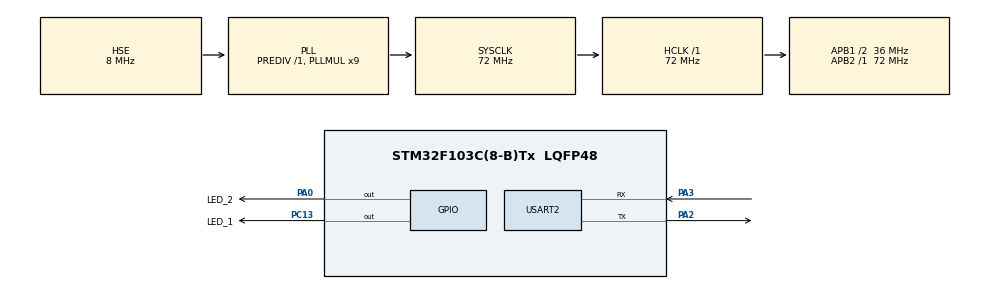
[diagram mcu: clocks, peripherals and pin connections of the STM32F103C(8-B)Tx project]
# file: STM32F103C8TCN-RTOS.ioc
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FREERTOS.Tasks01=defaultTask,0,128,StartDefaultTask,Default,NULL,Dynamic,NULL,NULL;myTask02,-3,128,StartTask02,Default,NULL,Dynamic,NULL,NULL
FREERTOS.configUSE_NEWLIB_REENTRANT=1
Mcu.Family=STM32F1
Mcu.Name=STM32F103C(8-B)Tx
Mcu.Package=LQFP48
NVIC.PriorityGroup=NVIC_PRIORITYGROUP_4
NVIC.TIM1_UP_IRQn=true\:15\:0\:false\:false\:true\:false\:false\:true\:true
NVIC.TimeBase=TIM1_UP_IRQn
NVIC.TimeBaseIP=TIM1
PA0-WKUP.GPIO_Label=LED_2
PA0-WKUP.Signal=GPIO_Output
PA2.Mode=Asynchronous
PA2.Signal=USART2_TX
PA3.Mode=Asynchronous
PA3.Signal=USART2_RX
PC13-TAMPER-RTC.GPIO_Label=LED_1
PC13-TAMPER-RTC.Signal=GPIO_Output
PD0-OSC_IN.Mode=HSE-External-Oscillator
PD0-OSC_IN.Signal=RCC_OSC_IN
PD1-OSC_OUT.Mode=HSE-External-Oscillator
PD1-OSC_OUT.Signal=RCC_OSC_OUT
ProjectManager.HeapSize=0x200
ProjectManager.StackSize=0x400
ProjectManager.TargetToolchain=STM32CubeIDE
RCC.AHBFreq_Value=72000000
RCC.APB1CLKDivider=RCC_HCLK_DIV2
RCC.APB1Freq_Value=36000000
RCC.APB1TimFreq_Value=72000000
RCC.APB2Freq_Value=72000000
RCC.APB2TimFreq_Value=72000000
RCC.HCLKFreq_Value=72000000
RCC.PLLMUL=RCC_PLL_MUL9
RCC.PLLSourceVirtual=RCC_PLLSOURCE_HSE
RCC.SYSCLKFreq_VALUE=72000000
RCC.SYSCLKSource=RCC_SYSCLKSOURCE_PLLCLK
RCC.USBFreq_Value=72000000
USART2.VirtualMode=VM_ASYNC
VP_FREERTOS_VS_CMSIS_V1.Mode=CMSIS_V1
VP_SYS_VS_tim1.Mode=TIM1
board=custom

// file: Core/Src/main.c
/* USER CODE BEGIN Header */
/**
  ******************************************************************************
  * @file           : main.c
  * @brief          : Main program body
  ******************************************************************************
  * @attention
  *
  * Copyright (c) 2023 STMicroelectronics.
  * All rights reserved.
  *
  * This software is licensed under terms that can be found in the LICENSE file
  * in the root directory of this software component.
  * If no LICENSE file comes with this software, it is provided AS-IS.
  *
  ******************************************************************************
  */
/* USER CODE END Header */
#include "main.h"
#include "cmsis_os.h"
#include "usart.h"
#include "gpio.h"

void SystemClock_Config(void);
void MX_FREERTOS_Init(void);

int main(void)
{

  /* MCU Configuration--------------------------------------------------------*/

  /* Reset of all peripherals, Initializes the Flash interface and the Systick. */
  HAL_Init();

  /* Configure the system clock */
  SystemClock_Config();

  /* Initialize all configured peripherals */
  MX_GPIO_Init();
  MX_USART2_UART_Init();

  /* Call init function for freertos objects (in freertos.c) */
  MX_FREERTOS_Init();

  /* Start scheduler */
  osKernelStart();
  /* We should never get here as control is now taken by the scheduler */
  /* Infinite loop */
  while (1)
  {

  }
}

void SystemClock_Config(void)
{
  RCC_OscInitTypeDef RCC_OscInitStruct = {0};
  RCC_ClkInitTypeDef RCC_ClkInitStruct = {0};

  /** Initializes the RCC Oscillators according to the specified parameters
  * in the RCC_OscInitTypeDef structure.
  */
  RCC_OscInitStruct.OscillatorType = RCC_OSCILLATORTYPE_HSE;
  RCC_OscInitStruct.HSEState = RCC_HSE_ON;
  RCC_OscInitStruct.HSEPredivValue = RCC_HSE_PREDIV_DIV1;
  RCC_OscInitStruct.HSIState = RCC_HSI_ON;
  RCC_OscInitStruct.PLL.PLLState = RCC_PLL_ON;
  RCC_OscInitStruct.PLL.PLLSource = RCC_PLLSOURCE_HSE;
  RCC_OscInitStruct.PLL.PLLMUL = RCC_PLL_MUL9;
  if (HAL_RCC_OscConfig(&RCC_OscInitStruct) != HAL_OK)
  {
    Error_Handler();
  }

  /** Initializes the CPU, AHB and APB buses clocks
  */
  RCC_ClkInitStruct.ClockType = RCC_CLOCKTYPE_HCLK|RCC_CLOCKTYPE_SYSCLK
                              |RCC_CLOCKTYPE_PCLK1|RCC_CLOCKTYPE_PCLK2;
  RCC_ClkInitStruct.SYSCLKSource = RCC_SYSCLKSOURCE_PLLCLK;
  RCC_ClkInitStruct.AHBCLKDivider = RCC_SYSCLK_DIV1;
  RCC_ClkInitStruct.APB1CLKDivider = RCC_HCLK_DIV2;
  RCC_ClkInitStruct.APB2CLKDivider = RCC_HCLK_DIV1;

  if (HAL_RCC_ClockConfig(&RCC_ClkInitStruct, FLASH_LATENCY_2) != HAL_OK)
  {
    Error_Handler();
  }
}

void HAL_TIM_PeriodElapsedCallback(TIM_HandleTypeDef *htim)
{
  if (htim->Instance == TIM1) {
    HAL_IncTick();
  }
}

void Error_Handler(void)
{
  __disable_irq();
  while (1)
  {
  }
}

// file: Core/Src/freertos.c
/* USER CODE BEGIN Header */
/**
  ******************************************************************************
  * File Name          : freertos.c
  * Description        : Code for freertos applications
  ******************************************************************************
  * @attention
  *
  * Copyright (c) 2023 STMicroelectronics.
  * All rights reserved.
  *
  * This software is licensed under terms that can be found in the LICENSE file
  * in the root directory of this software component.
  * If no LICENSE file comes with this software, it is provided AS-IS.
  *
  ******************************************************************************
  */
/* USER CODE END Header */

#include "FreeRTOS.h"
#include "task.h"
#include "main.h"
#include "cmsis_os.h"

osThreadId defaultTaskHandle;
osThreadId myTask02Handle;

void StartDefaultTask(void const * argument);
void StartTask02(void const * argument);

void MX_FREERTOS_Init(void); /* (MISRA C 2004 rule 8.1) */

/* GetIdleTaskMemory prototype (linked to static allocation support) */
void vApplicationGetIdleTaskMemory( StaticTask_t **ppxIdleTaskTCBBuffer, StackType_t **ppxIdleTaskStackBuffer, uint32_t *pulIdleTaskStackSize );

/* USER CODE BEGIN GET_IDLE_TASK_MEMORY */
static StaticTask_t xIdleTaskTCBBuffer;
static StackType_t xIdleStack[configMINIMAL_STACK_SIZE];

void vApplicationGetIdleTaskMemory( StaticTask_t **ppxIdleTaskTCBBuffer, StackType_t **ppxIdleTaskStackBuffer, uint32_t *pulIdleTaskStackSize )
{
  *ppxIdleTaskTCBBuffer = &xIdleTaskTCBBuffer;
  *ppxIdleTaskStackBuffer = &xIdleStack[0];
  *pulIdleTaskStackSize = configMINIMAL_STACK_SIZE;
  /* place for user code */
}
/* USER CODE END GET_IDLE_TASK_MEMORY */

void MX_FREERTOS_Init(void) {

  /* Create the thread(s) */
  /* definition and creation of defaultTask */
  osThreadDef(defaultTask, StartDefaultTask, osPriorityNormal, 0, 128);
  defaultTaskHandle = osThreadCreate(osThread(defaultTask), NULL);

  /* definition and creation of myTask02 */
  osThreadDef(myTask02, StartTask02, osPriorityIdle, 0, 128);
  myTask02Handle = osThreadCreate(osThread(myTask02), NULL);

}

void StartDefaultTask(void const * argument)
{
  /* USER CODE BEGIN StartDefaultTask */
  /* Infinite loop */
  for(;;)
  {
    HAL_GPIO_TogglePin(LED_1_GPIO_Port, LED_1_Pin);
    osDelay(300);
  }
  /* USER CODE END StartDefaultTask */
}

void StartTask02(void const * argument)
{
  /* USER CODE BEGIN StartTask02 */
  /* Infinite loop */
  for(;;)
  {
    HAL_GPIO_TogglePin(LED_2_GPIO_Port, LED_2_Pin);
    osDelay(100);
  }
  /* USER CODE END StartTask02 */
}
